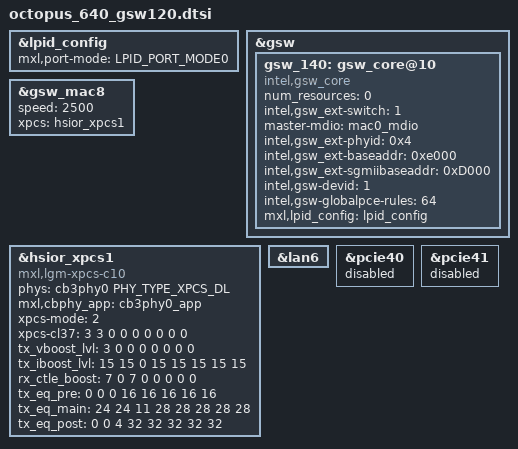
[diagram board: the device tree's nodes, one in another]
// SPDX-License-Identifier: GPL-2.0
/*
 * This file created for LGMC bring up only.
 * It will be removed after bring up.
 *
 * Copyright (C) 2024 MaxLinear, Inc.
 */

&lpid_config {
	mxl,port-mode = <LPID_PORT_MODE0>;
};

&gsw {
	gsw_140: gsw_core@10 {
		compatible = "intel,gsw_core";
		num_resources = <0>;
		intel,gsw_ext-switch = <1>;
		master-mdio = <&mac0_mdio>;
		intel,gsw_ext-phyid = <0x4>;
		intel,gsw_ext-baseaddr = <0xe000>;
		intel,gsw_ext-sgmiibaseaddr = <0xD000>;
		intel,gsw-devid = <1>;
		intel,gsw-globalpce-rules = <64>;
		mxl,lpid_config = <&lpid_config>;
	};
};

&gsw_mac8 {
	speed = <2500>;
	xpcs = <&hsior_xpcs1>;
};

&hsior_xpcs1 {
	status = "okay";
	/delete-property/ slave;

	compatible = "mxl,lgm-xpcs-c10";
	phys = <&cb3phy0 PHY_TYPE_XPCS_DL>;
	mxl,cbphy_app = <&cb3phy0_app>;

	xpcs-mode = <2>;
	xpcs-cl37 = <3 3 0 0 0 0 0 0 0>; /* <0> - disable, <1> - SGMII MAC side, <2> - SGMII PHY side, <3> - BaseX */
	tx_vboost_lvl = <3 0 0 0 0 0 0 0>;
	tx_iboost_lvl = <15 15 0 15 15 15 15 15>;
	rx_ctle_boost = <7 0 7 0 0 0 0 0>;
	tx_eq_pre = <0 0 0 16 16 16 16 16>;
	tx_eq_main = <24 24 11 28 28 28 28 28>;
	tx_eq_post = <0 0 4 32 32 32 32 32>;
};

&lan6 {
	status = "okay";
};

&pcie40 {
	status = "disabled";
};

&pcie41 {
	status = "disabled";
};
